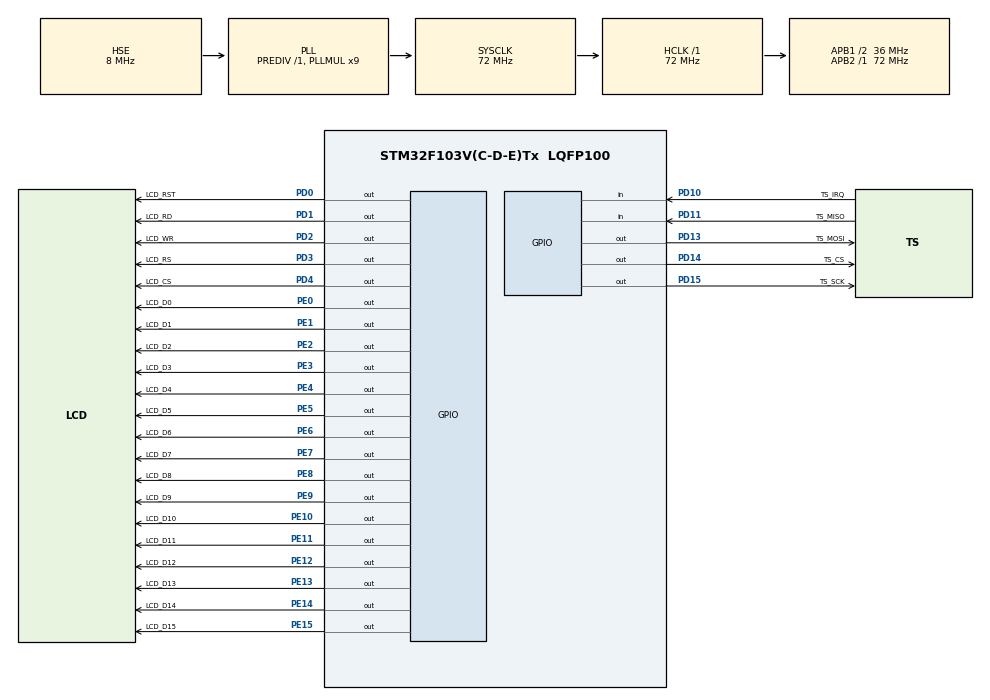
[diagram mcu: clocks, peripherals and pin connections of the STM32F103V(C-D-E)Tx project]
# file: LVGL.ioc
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Mcu.Family=STM32F1
Mcu.Name=STM32F103V(C-D-E)Tx
Mcu.Package=LQFP100
NVIC.PriorityGroup=NVIC_PRIORITYGROUP_4
NVIC.TIM6_IRQn=true\:15\:0\:false\:false\:true\:false\:true\:true
NVIC.TimeBase=TIM6_IRQn
NVIC.TimeBaseIP=TIM6
OSC_IN.Mode=HSE-External-Oscillator
OSC_IN.Signal=RCC_OSC_IN
OSC_OUT.Mode=HSE-External-Oscillator
OSC_OUT.Signal=RCC_OSC_OUT
PA13.Mode=Trace_Asynchronous_SW
PA13.Signal=SYS_JTMS-SWDIO
PA14.Mode=Trace_Asynchronous_SW
PA14.Signal=SYS_JTCK-SWCLK
PB3.Mode=Trace_Asynchronous_SW
PB3.Signal=SYS_JTDO-TRACESWO
PD0.GPIO_Label=LCD_RST
PD0.GPIO_Speed=GPIO_SPEED_FREQ_LOW
PD0.PinState=GPIO_PIN_SET
PD0.Signal=GPIO_Output
PD1.GPIO_Label=LCD_RD
PD1.GPIO_Speed=GPIO_SPEED_FREQ_HIGH
PD1.PinState=GPIO_PIN_SET
PD1.Signal=GPIO_Output
PD10.GPIO_Label=TS_IRQ
PD10.Signal=GPIO_Input
PD11.GPIO_Label=TS_MISO
PD11.Signal=GPIO_Input
PD13.GPIO_Label=TS_MOSI
PD13.GPIO_Speed=GPIO_SPEED_FREQ_HIGH
PD13.Signal=GPIO_Output
PD14.GPIO_Label=TS_CS
PD14.GPIO_Speed=GPIO_SPEED_FREQ_HIGH
PD14.PinState=GPIO_PIN_SET
PD14.Signal=GPIO_Output
PD15.GPIO_Label=TS_SCK
PD15.GPIO_Speed=GPIO_SPEED_FREQ_HIGH
PD15.PinState=GPIO_PIN_SET
PD15.Signal=GPIO_Output
PD2.GPIO_Label=LCD_WR
PD2.Signal=GPIO_Output
PD3.GPIO_Label=LCD_RS
PD3.GPIO_Speed=GPIO_SPEED_FREQ_HIGH
PD3.Signal=GPIO_Output
PD4.GPIO_Label=LCD_CS
PD4.GPIO_Speed=GPIO_SPEED_FREQ_HIGH
PD4.PinState=GPIO_PIN_SET
PD4.Signal=GPIO_Output
PE0.GPIO_Label=LCD_D0
PE0.GPIO_Speed=GPIO_SPEED_FREQ_HIGH
PE0.Signal=GPIO_Output
PE1.GPIO_Label=LCD_D1
PE1.GPIO_Speed=GPIO_SPEED_FREQ_HIGH
PE1.Signal=GPIO_Output
PE10.GPIO_Label=LCD_D10
PE10.GPIO_Speed=GPIO_SPEED_FREQ_HIGH
PE10.Signal=GPIO_Output
PE11.GPIO_Label=LCD_D11
PE11.GPIO_Speed=GPIO_SPEED_FREQ_HIGH
PE11.Signal=GPIO_Output
PE12.GPIO_Label=LCD_D12
PE12.GPIO_Speed=GPIO_SPEED_FREQ_HIGH
PE12.Signal=GPIO_Output
PE13.GPIO_Label=LCD_D13
PE13.GPIO_Speed=GPIO_SPEED_FREQ_HIGH
PE13.Signal=GPIO_Output
PE14.GPIO_Label=LCD_D14
PE14.GPIO_Speed=GPIO_SPEED_FREQ_HIGH
PE14.Signal=GPIO_Output
PE15.GPIO_Label=LCD_D15
PE15.GPIO_Speed=GPIO_SPEED_FREQ_HIGH
PE15.Signal=GPIO_Output
PE2.GPIO_Label=LCD_D2
PE2.GPIO_Speed=GPIO_SPEED_FREQ_HIGH
PE2.Signal=GPIO_Output
PE3.GPIO_Label=LCD_D3
PE3.GPIO_Speed=GPIO_SPEED_FREQ_HIGH
PE3.Signal=GPIO_Output
PE4.GPIO_Label=LCD_D4
PE4.GPIO_Speed=GPIO_SPEED_FREQ_HIGH
PE4.Signal=GPIO_Output
PE5.GPIO_Label=LCD_D5
PE5.GPIO_Speed=GPIO_SPEED_FREQ_HIGH
PE5.Signal=GPIO_Output
PE6.GPIO_Label=LCD_D6
PE6.GPIO_Speed=GPIO_SPEED_FREQ_HIGH
PE6.Signal=GPIO_Output
PE7.GPIO_Label=LCD_D7
PE7.GPIO_Speed=GPIO_SPEED_FREQ_HIGH
PE7.Signal=GPIO_Output
PE8.GPIO_Label=LCD_D8
PE8.GPIO_Speed=GPIO_SPEED_FREQ_HIGH
PE8.Signal=GPIO_Output
PE9.GPIO_Label=LCD_D9
PE9.GPIO_Speed=GPIO_SPEED_FREQ_HIGH
PE9.Signal=GPIO_Output
ProjectManager.HeapSize=0x200
ProjectManager.StackSize=0x800
ProjectManager.TargetToolchain=STM32CubeIDE
RCC.AHBFreq_Value=72000000
RCC.APB1CLKDivider=RCC_HCLK_DIV2
RCC.APB1Freq_Value=36000000
RCC.APB1TimFreq_Value=72000000
RCC.APB2Freq_Value=72000000
RCC.APB2TimFreq_Value=72000000
RCC.HCLKFreq_Value=72000000
RCC.PLLMUL=RCC_PLL_MUL9
RCC.PLLSourceVirtual=RCC_PLLSOURCE_HSE
RCC.SYSCLKFreq_VALUE=72000000
RCC.SYSCLKSource=RCC_SYSCLKSOURCE_PLLCLK
RCC.USBFreq_Value=72000000
VP_SYS_VS_tim6.Mode=TIM6
board=custom

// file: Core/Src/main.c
/* USER CODE BEGIN Header */
/**
  ******************************************************************************
  * @file           : main.c
  * @brief          : Main program body
  ******************************************************************************
  * @attention
  *
  * Copyright (c) 2023 STMicroelectronics.
  * All rights reserved.
  *
  * This software is licensed under terms that can be found in the LICENSE file
  * in the root directory of this software component.
  * If no LICENSE file comes with this software, it is provided AS-IS.
  *
  ******************************************************************************
  */
/* USER CODE END Header */
#include "main.h"

void SystemClock_Config(void);
static void MX_GPIO_Init(void);

/* USER CODE BEGIN 0 */
void mainApp(void);

/* USER CODE END 0 */

int main(void)
{

  /* MCU Configuration--------------------------------------------------------*/

  /* Reset of all peripherals, Initializes the Flash interface and the Systick. */
  HAL_Init();

  /* Configure the system clock */
  SystemClock_Config();

  /* Initialize all configured peripherals */
  MX_GPIO_Init();

  /* Infinite loop */
  /* USER CODE BEGIN WHILE */
  mainApp();
  while (1)
  {
    /* USER CODE END WHILE */

  }
}

void SystemClock_Config(void)
{
  RCC_OscInitTypeDef RCC_OscInitStruct = {0};
  RCC_ClkInitTypeDef RCC_ClkInitStruct = {0};

  /** Initializes the RCC Oscillators according to the specified parameters
  * in the RCC_OscInitTypeDef structure.
  */
  RCC_OscInitStruct.OscillatorType = RCC_OSCILLATORTYPE_HSE;
  RCC_OscInitStruct.HSEState = RCC_HSE_ON;
  RCC_OscInitStruct.HSEPredivValue = RCC_HSE_PREDIV_DIV1;
  RCC_OscInitStruct.HSIState = RCC_HSI_ON;
  RCC_OscInitStruct.PLL.PLLState = RCC_PLL_ON;
  RCC_OscInitStruct.PLL.PLLSource = RCC_PLLSOURCE_HSE;
  RCC_OscInitStruct.PLL.PLLMUL = RCC_PLL_MUL9;
  if (HAL_RCC_OscConfig(&RCC_OscInitStruct) != HAL_OK)
  {
    Error_Handler();
  }

  /** Initializes the CPU, AHB and APB buses clocks
  */
  RCC_ClkInitStruct.ClockType = RCC_CLOCKTYPE_HCLK|RCC_CLOCKTYPE_SYSCLK
                              |RCC_CLOCKTYPE_PCLK1|RCC_CLOCKTYPE_PCLK2;
  RCC_ClkInitStruct.SYSCLKSource = RCC_SYSCLKSOURCE_PLLCLK;
  RCC_ClkInitStruct.AHBCLKDivider = RCC_SYSCLK_DIV1;
  RCC_ClkInitStruct.APB1CLKDivider = RCC_HCLK_DIV2;
  RCC_ClkInitStruct.APB2CLKDivider = RCC_HCLK_DIV1;

  if (HAL_RCC_ClockConfig(&RCC_ClkInitStruct, FLASH_LATENCY_2) != HAL_OK)
  {
    Error_Handler();
  }
}

static void MX_GPIO_Init(void)
{
  GPIO_InitTypeDef GPIO_InitStruct = {0};

  /* GPIO Ports Clock Enable */
  __HAL_RCC_GPIOE_CLK_ENABLE();
  __HAL_RCC_GPIOD_CLK_ENABLE();
  __HAL_RCC_GPIOA_CLK_ENABLE();
  __HAL_RCC_GPIOB_CLK_ENABLE();

  /*Configure GPIO pin Output Level */
  HAL_GPIO_WritePin(GPIOE, LCD_D2_Pin|LCD_D3_Pin|LCD_D4_Pin|LCD_D5_Pin
                          |LCD_D6_Pin|LCD_D7_Pin|LCD_D8_Pin|LCD_D9_Pin
                          |LCD_D10_Pin|LCD_D11_Pin|LCD_D12_Pin|LCD_D13_Pin
                          |LCD_D14_Pin|LCD_D15_Pin|LCD_D0_Pin|LCD_D1_Pin, GPIO_PIN_RESET);

  /*Configure GPIO pin Output Level */
  HAL_GPIO_WritePin(GPIOD, TS_MOSI_Pin|LCD_WR_Pin|LCD_RS_Pin, GPIO_PIN_RESET);

  /*Configure GPIO pin Output Level */
  HAL_GPIO_WritePin(GPIOD, TS_CS_Pin|TS_SCK_Pin|LCD_RST_Pin|LCD_RD_Pin
                          |LCD_CS_Pin, GPIO_PIN_SET);

  /*Configure GPIO pins : LCD_D2_Pin LCD_D3_Pin LCD_D4_Pin LCD_D5_Pin
                           LCD_D6_Pin LCD_D7_Pin LCD_D8_Pin LCD_D9_Pin
                           LCD_D10_Pin LCD_D11_Pin LCD_D12_Pin LCD_D13_Pin
                           LCD_D14_Pin LCD_D15_Pin LCD_D0_Pin LCD_D1_Pin */
  GPIO_InitStruct.Pin = LCD_D2_Pin|LCD_D3_Pin|LCD_D4_Pin|LCD_D5_Pin
                          |LCD_D6_Pin|LCD_D7_Pin|LCD_D8_Pin|LCD_D9_Pin
                          |LCD_D10_Pin|LCD_D11_Pin|LCD_D12_Pin|LCD_D13_Pin
                          |LCD_D14_Pin|LCD_D15_Pin|LCD_D0_Pin|LCD_D1_Pin;
  GPIO_InitStruct.Mode = GPIO_MODE_OUTPUT_PP;
  GPIO_InitStruct.Pull = GPIO_NOPULL;
  GPIO_InitStruct.Speed = GPIO_SPEED_FREQ_HIGH;
  HAL_GPIO_Init(GPIOE, &GPIO_InitStruct);

  /*Configure GPIO pins : TS_IRQ_Pin TS_MISO_Pin */
  GPIO_InitStruct.Pin = TS_IRQ_Pin|TS_MISO_Pin;
  GPIO_InitStruct.Mode = GPIO_MODE_INPUT;
  GPIO_InitStruct.Pull = GPIO_NOPULL;
  HAL_GPIO_Init(GPIOD, &GPIO_InitStruct);

  /*Configure GPIO pins : TS_MOSI_Pin TS_CS_Pin TS_SCK_Pin LCD_RD_Pin
                           LCD_RS_Pin LCD_CS_Pin */
  GPIO_InitStruct.Pin = TS_MOSI_Pin|TS_CS_Pin|TS_SCK_Pin|LCD_RD_Pin
                          |LCD_RS_Pin|LCD_CS_Pin;
  GPIO_InitStruct.Mode = GPIO_MODE_OUTPUT_PP;
  GPIO_InitStruct.Pull = GPIO_NOPULL;
  GPIO_InitStruct.Speed = GPIO_SPEED_FREQ_HIGH;
  HAL_GPIO_Init(GPIOD, &GPIO_InitStruct);

  /*Configure GPIO pins : LCD_RST_Pin LCD_WR_Pin */
  GPIO_InitStruct.Pin = LCD_RST_Pin|LCD_WR_Pin;
  GPIO_InitStruct.Mode = GPIO_MODE_OUTPUT_PP;
  GPIO_InitStruct.Pull = GPIO_NOPULL;
  GPIO_InitStruct.Speed = GPIO_SPEED_FREQ_LOW;
  HAL_GPIO_Init(GPIOD, &GPIO_InitStruct);

}

/* USER CODE BEGIN 4 */
int _write(int file, char *ptr, int len)
{
  /* Implement your write code here, this is used by puts and printf for example */
  int i=0;
  for(i=0 ; i<len ; i++)
    ITM_SendChar((*ptr++));
  return len;
}
/* USER CODE END 4 */

void HAL_TIM_PeriodElapsedCallback(TIM_HandleTypeDef *htim)
{
  if (htim->Instance == TIM6) {
    HAL_IncTick();
  }
}

void Error_Handler(void)
{
  __disable_irq();
  while (1)
  {
  }
}
